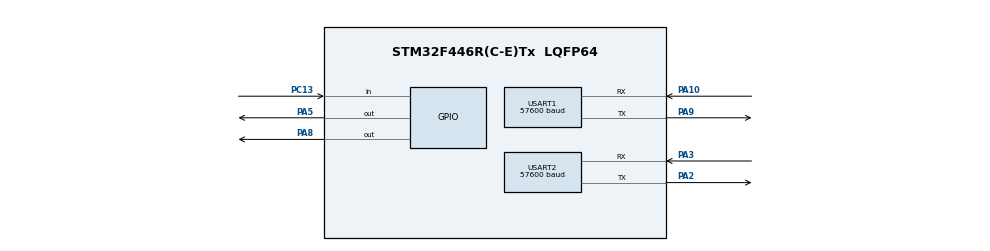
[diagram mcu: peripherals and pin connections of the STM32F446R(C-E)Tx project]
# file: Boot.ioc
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Mcu.Family=STM32F4
Mcu.Name=STM32F446R(C-E)Tx
Mcu.Package=LQFP64
NVIC.PriorityGroup=NVIC_PRIORITYGROUP_0
PA10.Mode=Asynchronous
PA10.Signal=USART1_RX
PA2.Mode=Asynchronous
PA2.Signal=USART2_TX
PA3.Mode=Asynchronous
PA3.Signal=USART2_RX
PA5.Signal=GPIO_Output
PA8.Signal=GPIO_Output
PA9.Mode=Asynchronous
PA9.Signal=USART1_TX
PC13.Signal=GPIO_Input
PH0-OSC_IN.Mode=HSE-External-Clock-Source
PH0-OSC_IN.Signal=RCC_OSC_IN
PH1-OSC_OUT.Mode=HSE-External-Clock-Source
PH1-OSC_OUT.Signal=RCC_OSC_OUT
ProjectManager.HeapSize=0x200
ProjectManager.StackSize=0x400
ProjectManager.TargetToolchain=STM32CubeIDE
RCC.AHBFreq_Value=180000000
RCC.APB1CLKDivider=RCC_HCLK_DIV4
RCC.APB1Freq_Value=45000000
RCC.APB1TimFreq_Value=90000000
RCC.APB2CLKDivider=RCC_HCLK_DIV2
RCC.APB2Freq_Value=90000000
RCC.APB2TimFreq_Value=180000000
RCC.CortexFreq_Value=180000000
RCC.FLatency-AdvancedSettings=FLASH_LATENCY_5
RCC.HCLKFreq_Value=180000000
RCC.HSE_VALUE=8000000
RCC.HSI_VALUE=16000000
RCC.LSE_VALUE=32768
RCC.PLLM=4
RCC.PLLN=180
RCC.PLLSourceVirtual=RCC_PLLSOURCE_HSE
RCC.SYSCLKFreq_VALUE=180000000
RCC.SYSCLKSource=RCC_SYSCLKSOURCE_PLLCLK
RCC.USBFreq_Value=180000000
RCC.VCOOutputFreq_Value=360000000
USART1.BaudRate=57600
USART1.Parity=PARITY_EVEN
USART1.VirtualMode=VM_ASYNC
USART1.WordLength=WORDLENGTH_9B
USART2.BaudRate=57600
USART2.Parity=PARITY_EVEN
USART2.VirtualMode=VM_ASYNC
USART2.WordLength=WORDLENGTH_9B
board=NUCLEO-F446RE

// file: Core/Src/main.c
/* USER CODE BEGIN Header */
/**
  ******************************************************************************
  * @file           : main.c
  * @brief          : Main program body
  ******************************************************************************
  * @attention
  *
  * Copyright (c) 2023 STMicroelectronics.
  * All rights reserved.
  *
  * This software is licensed under terms that can be found in the LICENSE file
  * in the root directory of this software component.
  * If no LICENSE file comes with this software, it is provided AS-IS.
  *
  ******************************************************************************
  */
/* USER CODE END Header */
#include "main.h"

/* USER CODE BEGIN Includes */
#include "app.h"
/* USER CODE END Includes */

void SystemClock_Config(void);
static void MX_GPIO_Init(void);
static void MX_USART2_UART_Init(void);
static void MX_USART1_UART_Init(void);

int main(void)
{

  /* MCU Configuration--------------------------------------------------------*/

  /* Reset of all peripherals, Initializes the Flash interface and the Systick. */
  HAL_Init();

  /* Configure the system clock */
  SystemClock_Config();

  /* Initialize all configured peripherals */
  MX_GPIO_Init();
  MX_USART2_UART_Init();
  MX_USART1_UART_Init();
  /* USER CODE BEGIN 2 */
  /* Initialize the bootloader application. */
  AppInit();
  /* USER CODE END 2 */

  /* Infinite loop */
  /* USER CODE BEGIN WHILE */
  while (1)
  {
    /* Run the bootloader application. */
    AppTask();
    /* USER CODE END WHILE */

  }
}

void SystemClock_Config(void)
{
  LL_FLASH_SetLatency(LL_FLASH_LATENCY_5);
  while(LL_FLASH_GetLatency()!= LL_FLASH_LATENCY_5)
  {
  }
  LL_PWR_SetRegulVoltageScaling(LL_PWR_REGU_VOLTAGE_SCALE1);
  LL_PWR_EnableOverDriveMode();
  LL_RCC_HSE_EnableBypass();
  LL_RCC_HSE_Enable();

   /* Wait till HSE is ready */
  while(LL_RCC_HSE_IsReady() != 1)
  {

  }
  LL_RCC_PLL_ConfigDomain_SYS(LL_RCC_PLLSOURCE_HSE, LL_RCC_PLLM_DIV_4, 180, LL_RCC_PLLP_DIV_2);
  LL_RCC_PLL_Enable();

   /* Wait till PLL is ready */
  while(LL_RCC_PLL_IsReady() != 1)
  {

  }
  while (LL_PWR_IsActiveFlag_VOS() == 0)
  {
  }
  LL_RCC_SetAHBPrescaler(LL_RCC_SYSCLK_DIV_1);
  LL_RCC_SetAPB1Prescaler(LL_RCC_APB1_DIV_4);
  LL_RCC_SetAPB2Prescaler(LL_RCC_APB2_DIV_2);
  LL_RCC_SetSysClkSource(LL_RCC_SYS_CLKSOURCE_PLL);

   /* Wait till System clock is ready */
  while(LL_RCC_GetSysClkSource() != LL_RCC_SYS_CLKSOURCE_STATUS_PLL)
  {

  }
  LL_SetSystemCoreClock(180000000);

   /* Update the time base */
  if (HAL_InitTick (TICK_INT_PRIORITY) != HAL_OK)
  {
    Error_Handler();
  }
  LL_RCC_SetTIMPrescaler(LL_RCC_TIM_PRESCALER_TWICE);
}

static void MX_USART1_UART_Init(void)
{

  /* USER CODE BEGIN USART1_Init 0 */
  /* Note that the USART initialization that follows here is don't care. It is
   * reconfigured upon bootloader initialization with function MbRtuInit().
   */
  /* USER CODE END USART1_Init 0 */

  LL_USART_InitTypeDef USART_InitStruct = {0};

  LL_GPIO_InitTypeDef GPIO_InitStruct = {0};

  /* Peripheral clock enable */
  LL_APB2_GRP1_EnableClock(LL_APB2_GRP1_PERIPH_USART1);

  LL_AHB1_GRP1_EnableClock(LL_AHB1_GRP1_PERIPH_GPIOA);
  /**USART1 GPIO Configuration
  PA9   ------> USART1_TX
  PA10   ------> USART1_RX
  */
  GPIO_InitStruct.Pin = LL_GPIO_PIN_9|LL_GPIO_PIN_10;
  GPIO_InitStruct.Mode = LL_GPIO_MODE_ALTERNATE;
  GPIO_InitStruct.Speed = LL_GPIO_SPEED_FREQ_VERY_HIGH;
  GPIO_InitStruct.OutputType = LL_GPIO_OUTPUT_PUSHPULL;
  GPIO_InitStruct.Pull = LL_GPIO_PULL_NO;
  GPIO_InitStruct.Alternate = LL_GPIO_AF_7;
  LL_GPIO_Init(GPIOA, &GPIO_InitStruct);

  USART_InitStruct.BaudRate = 57600;
  USART_InitStruct.DataWidth = LL_USART_DATAWIDTH_9B;
  USART_InitStruct.StopBits = LL_USART_STOPBITS_1;
  USART_InitStruct.Parity = LL_USART_PARITY_EVEN;
  USART_InitStruct.TransferDirection = LL_USART_DIRECTION_TX_RX;
  USART_InitStruct.HardwareFlowControl = LL_USART_HWCONTROL_NONE;
  USART_InitStruct.OverSampling = LL_USART_OVERSAMPLING_16;
  LL_USART_Init(USART1, &USART_InitStruct);
  LL_USART_ConfigAsyncMode(USART1);
  LL_USART_Enable(USART1);

}

static void MX_USART2_UART_Init(void)
{

  LL_USART_InitTypeDef USART_InitStruct = {0};

  LL_GPIO_InitTypeDef GPIO_InitStruct = {0};

  /* Peripheral clock enable */
  LL_APB1_GRP1_EnableClock(LL_APB1_GRP1_PERIPH_USART2);

  LL_AHB1_GRP1_EnableClock(LL_AHB1_GRP1_PERIPH_GPIOA);
  /**USART2 GPIO Configuration
  PA2   ------> USART2_TX
  PA3   ------> USART2_RX
  */
  GPIO_InitStruct.Pin = LL_GPIO_PIN_2|LL_GPIO_PIN_3;
  GPIO_InitStruct.Mode = LL_GPIO_MODE_ALTERNATE;
  GPIO_InitStruct.Speed = LL_GPIO_SPEED_FREQ_VERY_HIGH;
  GPIO_InitStruct.OutputType = LL_GPIO_OUTPUT_PUSHPULL;
  GPIO_InitStruct.Pull = LL_GPIO_PULL_NO;
  GPIO_InitStruct.Alternate = LL_GPIO_AF_7;
  LL_GPIO_Init(GPIOA, &GPIO_InitStruct);

  /* USER CODE BEGIN USART2_Init 1 */
  /* Note that the USART initialization that follows here is don't care. It is
   * reconfigured upon bootloader initialization with function MbRtuInit().
   */
  /* USER CODE END USART2_Init 1 */
  USART_InitStruct.BaudRate = 57600;
  USART_InitStruct.DataWidth = LL_USART_DATAWIDTH_9B;
  USART_InitStruct.StopBits = LL_USART_STOPBITS_1;
  USART_InitStruct.Parity = LL_USART_PARITY_EVEN;
  USART_InitStruct.TransferDirection = LL_USART_DIRECTION_TX_RX;
  USART_InitStruct.HardwareFlowControl = LL_USART_HWCONTROL_NONE;
  USART_InitStruct.OverSampling = LL_USART_OVERSAMPLING_16;
  LL_USART_Init(USART2, &USART_InitStruct);
  LL_USART_ConfigAsyncMode(USART2);
  LL_USART_Enable(USART2);

}

static void MX_GPIO_Init(void)
{
  GPIO_InitTypeDef GPIO_InitStruct = {0};

  /* GPIO Ports Clock Enable */
  __HAL_RCC_GPIOC_CLK_ENABLE();
  __HAL_RCC_GPIOH_CLK_ENABLE();
  __HAL_RCC_GPIOA_CLK_ENABLE();

  /*Configure GPIO pin Output Level */
  HAL_GPIO_WritePin(GPIOA, GPIO_PIN_5|GPIO_PIN_8, GPIO_PIN_RESET);

  /*Configure GPIO pin : PC13 */
  GPIO_InitStruct.Pin = GPIO_PIN_13;
  GPIO_InitStruct.Mode = GPIO_MODE_INPUT;
  GPIO_InitStruct.Pull = GPIO_NOPULL;
  HAL_GPIO_Init(GPIOC, &GPIO_InitStruct);

  /*Configure GPIO pins : PA5 PA8 */
  GPIO_InitStruct.Pin = GPIO_PIN_5|GPIO_PIN_8;
  GPIO_InitStruct.Mode = GPIO_MODE_OUTPUT_PP;
  GPIO_InitStruct.Pull = GPIO_NOPULL;
  GPIO_InitStruct.Speed = GPIO_SPEED_FREQ_LOW;
  HAL_GPIO_Init(GPIOA, &GPIO_InitStruct);

}

void Error_Handler(void)
{
  __disable_irq();
  while (1)
  {
  }
}
